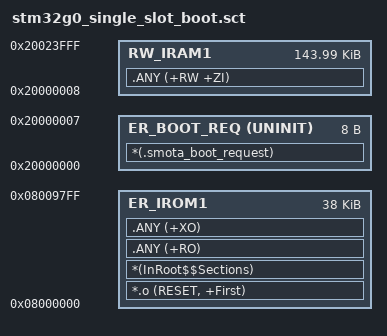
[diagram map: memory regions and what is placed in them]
LR_IROM1 0x08000000 0x00009800  {
  ER_IROM1 0x08000000 0x00009800  {
   *.o (RESET, +First)
   *(InRoot$$Sections)
   .ANY (+RO)
   .ANY (+XO)
  }
  ER_BOOT_REQ 0x20000000 UNINIT 0x00000008  {
   *(.smota_boot_request)
  }
  RW_IRAM1 0x20000008 0x00023FF8  {
   .ANY (+RW +ZI)
  }
}

